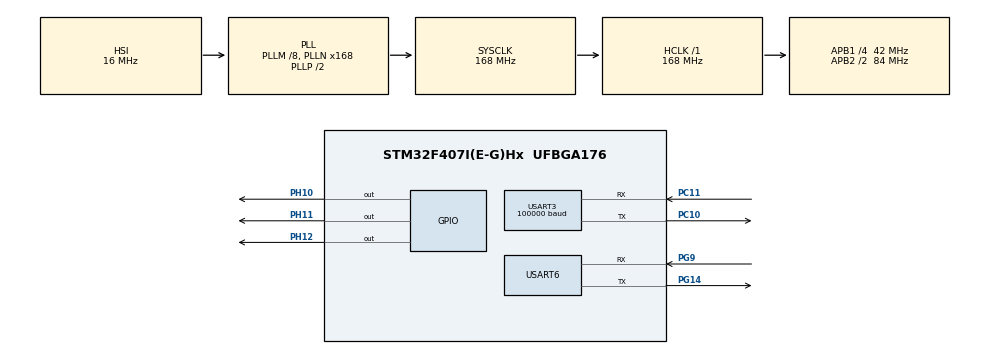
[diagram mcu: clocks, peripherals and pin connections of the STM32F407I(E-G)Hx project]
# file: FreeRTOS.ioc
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Dma.Request0=USART3_RX
Dma.USART3_RX.0.Direction=DMA_PERIPH_TO_MEMORY
Dma.USART3_RX.0.FIFOMode=DMA_FIFOMODE_DISABLE
Dma.USART3_RX.0.Instance=DMA1_Stream1
Dma.USART3_RX.0.MemDataAlignment=DMA_MDATAALIGN_BYTE
Dma.USART3_RX.0.MemInc=DMA_MINC_ENABLE
Dma.USART3_RX.0.Mode=DMA_CIRCULAR
Dma.USART3_RX.0.PeriphDataAlignment=DMA_PDATAALIGN_BYTE
Dma.USART3_RX.0.PeriphInc=DMA_PINC_DISABLE
Dma.USART3_RX.0.Priority=DMA_PRIORITY_VERY_HIGH
FREERTOS.Queues01=RCqueue,16,uint16_t,0,Dynamic,NULL,NULL
FREERTOS.Tasks01=LED_G,-2,256,LED_GTask,As weak,NULL,Dynamic,NULL,NULL;LED_R,-2,128,LED_RTask,As weak,NULL,Dynamic,NULL,NULL;UsartTask,0,128,usart_Task,Default,NULL,Dynamic,NULL,NULL
Mcu.Family=STM32F4
Mcu.Name=STM32F407I(E-G)Hx
Mcu.Package=UFBGA176
NVIC.DMA1_Stream1_IRQn=true\:5\:0\:false\:false\:true\:true\:false\:true\:true
NVIC.PriorityGroup=NVIC_PRIORITYGROUP_4
NVIC.TIM8_BRK_TIM12_IRQn=true\:15\:0\:false\:false\:true\:false\:false\:true\:true
NVIC.TimeBase=TIM8_BRK_TIM12_IRQn
NVIC.TimeBaseIP=TIM12
NVIC.USART3_IRQn=true\:5\:0\:false\:false\:true\:true\:true\:true\:true
NVIC.USART6_IRQn=true\:5\:0\:false\:false\:true\:true\:true\:true\:true
PA13.Mode=Serial_Wire
PA13.Signal=SYS_JTMS-SWDIO
PA14.Mode=Serial_Wire
PA14.Signal=SYS_JTCK-SWCLK
PC10.Mode=Asynchronous
PC10.Signal=USART3_TX
PC11.Mode=Asynchronous
PC11.Signal=USART3_RX
PG14.Mode=Asynchronous
PG14.Signal=USART6_TX
PG9.Mode=Asynchronous
PG9.Signal=USART6_RX
PH0-OSC_IN.Mode=HSE-External-Oscillator
PH0-OSC_IN.Signal=RCC_OSC_IN
PH1-OSC_OUT.Mode=HSE-External-Oscillator
PH1-OSC_OUT.Signal=RCC_OSC_OUT
PH10.PinState=GPIO_PIN_SET
PH10.Signal=GPIO_Output
PH11.GPIO_PuPd=GPIO_NOPULL
PH11.PinState=GPIO_PIN_RESET
PH11.Signal=GPIO_Output
PH12.GPIO_PuPd=GPIO_NOPULL
PH12.Signal=GPIO_Output
ProjectManager.HeapSize=0x200
ProjectManager.StackSize=0x400
ProjectManager.TargetToolchain=MDK-ARM V5.32
RCC.48MHZClocksFreq_Value=84000000
RCC.AHBFreq_Value=168000000
RCC.APB1CLKDivider=RCC_HCLK_DIV4
RCC.APB1Freq_Value=42000000
RCC.APB1TimFreq_Value=84000000
RCC.APB2CLKDivider=RCC_HCLK_DIV2
RCC.APB2Freq_Value=84000000
RCC.APB2TimFreq_Value=168000000
RCC.CortexFreq_Value=168000000
RCC.HCLKFreq_Value=168000000
RCC.HSE_VALUE=12000000
RCC.HSI_VALUE=16000000
RCC.LSE_VALUE=32768
RCC.PLLM=8
RCC.PLLN=168
RCC.SYSCLKFreq_VALUE=168000000
RCC.SYSCLKSource=RCC_SYSCLKSOURCE_PLLCLK
RCC.VCOOutputFreq_Value=336000000
USART3.BaudRate=100000
USART3.Parity=PARITY_EVEN
USART3.VirtualMode=VM_ASYNC
USART3.WordLength=WORDLENGTH_9B
USART6.VirtualMode=VM_ASYNC
VP_FREERTOS_VS_CMSIS_V1.Mode=CMSIS_V1
VP_SYS_VS_tim12.Mode=TIM12
board=custom

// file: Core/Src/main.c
/* USER CODE BEGIN Header */
/**
  ******************************************************************************
  * @file           : main.c
  * @brief          : Main program body
  ******************************************************************************
  * @attention
  *
  * Copyright (c) 2025 STMicroelectronics.
  * All rights reserved.
  *
  * This software is licensed under terms that can be found in the LICENSE file
  * in the root directory of this software component.
  * If no LICENSE file comes with this software, it is provided AS-IS.
  *
  ******************************************************************************
  */
/* USER CODE END Header */
#include "main.h"
#include "cmsis_os.h"
#include "dma.h"
#include "usart.h"
#include "gpio.h"

/* USER CODE BEGIN Includes */
#include "Usart1.h"
#include "Remote_Control.h"
/* USER CODE END Includes */

/* USER CODE BEGIN PV */
uint8_t sbus_buf[18];//遥控器的数据是18字节的
/* USER CODE END PV */

void SystemClock_Config(void);
void MX_FREERTOS_Init(void);
/* USER CODE BEGIN PFP */
void HAL_UART_RxCpltcallback(UART_HandleTypeDef *UartHandle);
/* USER CODE END PFP */

int main(void)
{

  /* MCU Configuration--------------------------------------------------------*/

  /* Reset of all peripherals, Initializes the Flash interface and the Systick. */
  HAL_Init();

  /* Configure the system clock */
  SystemClock_Config();

  /* Initialize all configured peripherals */
  MX_GPIO_Init();
  MX_DMA_Init();
  MX_USART3_UART_Init();
  MX_USART6_UART_Init();
  /* USER CODE BEGIN 2 */
  HAL_UART_Receive_DMA(&huart3, sbus_buf, 18);
  /* USER CODE END 2 */

  /* Call init function for freertos objects (in cmsis_os2.c) */
  MX_FREERTOS_Init();

  /* Start scheduler */
  osKernelStart();

  /* We should never get here as control is now taken by the scheduler */

  /* Infinite loop */
  while (1)
  {

  }
}

void SystemClock_Config(void)
{
  RCC_OscInitTypeDef RCC_OscInitStruct = {0};
  RCC_ClkInitTypeDef RCC_ClkInitStruct = {0};

  /** Configure the main internal regulator output voltage
  */
  __HAL_RCC_PWR_CLK_ENABLE();
  __HAL_PWR_VOLTAGESCALING_CONFIG(PWR_REGULATOR_VOLTAGE_SCALE1);

  /** Initializes the RCC Oscillators according to the specified parameters
  * in the RCC_OscInitTypeDef structure.
  */
  RCC_OscInitStruct.OscillatorType = RCC_OSCILLATORTYPE_HSI;
  RCC_OscInitStruct.HSIState = RCC_HSI_ON;
  RCC_OscInitStruct.HSICalibrationValue = RCC_HSICALIBRATION_DEFAULT;
  RCC_OscInitStruct.PLL.PLLState = RCC_PLL_ON;
  RCC_OscInitStruct.PLL.PLLSource = RCC_PLLSOURCE_HSI;
  RCC_OscInitStruct.PLL.PLLM = 8;
  RCC_OscInitStruct.PLL.PLLN = 168;
  RCC_OscInitStruct.PLL.PLLP = RCC_PLLP_DIV2;
  RCC_OscInitStruct.PLL.PLLQ = 4;
  if (HAL_RCC_OscConfig(&RCC_OscInitStruct) != HAL_OK)
  {
    Error_Handler();
  }

  /** Initializes the CPU, AHB and APB buses clocks
  */
  RCC_ClkInitStruct.ClockType = RCC_CLOCKTYPE_HCLK|RCC_CLOCKTYPE_SYSCLK
                              |RCC_CLOCKTYPE_PCLK1|RCC_CLOCKTYPE_PCLK2;
  RCC_ClkInitStruct.SYSCLKSource = RCC_SYSCLKSOURCE_PLLCLK;
  RCC_ClkInitStruct.AHBCLKDivider = RCC_SYSCLK_DIV1;
  RCC_ClkInitStruct.APB1CLKDivider = RCC_HCLK_DIV4;
  RCC_ClkInitStruct.APB2CLKDivider = RCC_HCLK_DIV2;

  if (HAL_RCC_ClockConfig(&RCC_ClkInitStruct, FLASH_LATENCY_5) != HAL_OK)
  {
    Error_Handler();
  }
}

void HAL_TIM_PeriodElapsedCallback(TIM_HandleTypeDef *htim)
{
  if (htim->Instance == TIM12)
  {
    HAL_IncTick();
  }
}

void Error_Handler(void)
{
  __disable_irq();
  while (1)
  {
  }
}

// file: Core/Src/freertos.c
/* USER CODE BEGIN Header */
/**
  ******************************************************************************
  * File Name          : freertos.c
  * Description        : Code for freertos applications
  ******************************************************************************
  * @attention
  *
  * Copyright (c) 2025 STMicroelectronics.
  * All rights reserved.
  *
  * This software is licensed under terms that can be found in the LICENSE file
  * in the root directory of this software component.
  * If no LICENSE file comes with this software, it is provided AS-IS.
  *
  ******************************************************************************
  */
/* USER CODE END Header */

#include "FreeRTOS.h"
#include "task.h"
#include "main.h"
#include "cmsis_os.h"

/* USER CODE BEGIN Includes */
#include "Usart1.h"
#include "usart.h"
/* USER CODE END Includes */

osThreadId LED_GHandle;
osThreadId LED_RHandle;
osThreadId UsartTaskHandle;
osMessageQId RCqueueHandle;

void LED_GTask(void const * argument);
void LED_RTask(void const * argument);
void usart_Task(void const * argument);

void MX_FREERTOS_Init(void); /* (MISRA C 2004 rule 8.1) */

/* GetIdleTaskMemory prototype (linked to static allocation support) */
void vApplicationGetIdleTaskMemory( StaticTask_t **ppxIdleTaskTCBBuffer, StackType_t **ppxIdleTaskStackBuffer, uint32_t *pulIdleTaskStackSize );

/* USER CODE BEGIN GET_IDLE_TASK_MEMORY */
static StaticTask_t xIdleTaskTCBBuffer;
static StackType_t xIdleStack[configMINIMAL_STACK_SIZE];

void vApplicationGetIdleTaskMemory( StaticTask_t **ppxIdleTaskTCBBuffer, StackType_t **ppxIdleTaskStackBuffer, uint32_t *pulIdleTaskStackSize )
{
  *ppxIdleTaskTCBBuffer = &xIdleTaskTCBBuffer;
  *ppxIdleTaskStackBuffer = &xIdleStack[0];
  *pulIdleTaskStackSize = configMINIMAL_STACK_SIZE;
  /* place for user code */
}
/* USER CODE END GET_IDLE_TASK_MEMORY */

void MX_FREERTOS_Init(void) {

  /* Create the queue(s) */
  /* definition and creation of RCqueue */
  osMessageQDef(RCqueue, 16, uint16_t);
  RCqueueHandle = osMessageCreate(osMessageQ(RCqueue), NULL);

  /* Create the thread(s) */
  /* definition and creation of LED_G */
  osThreadDef(LED_G, LED_GTask, osPriorityLow, 0, 256);
  LED_GHandle = osThreadCreate(osThread(LED_G), NULL);

  /* definition and creation of LED_R */
  osThreadDef(LED_R, LED_RTask, osPriorityLow, 0, 128);
  LED_RHandle = osThreadCreate(osThread(LED_R), NULL);

  /* definition and creation of UsartTask */
  osThreadDef(UsartTask, usart_Task, osPriorityNormal, 0, 128);
  UsartTaskHandle = osThreadCreate(osThread(UsartTask), NULL);

}

__weak void LED_GTask(void const * argument)
{
  for(;;)
  {
    osDelay(1);
  }
}

__weak void LED_RTask(void const * argument)
{
  for(;;)
  {
    osDelay(1);
  }
}

void usart_Task(void const * argument)
{
  /* USER CODE BEGIN usart_Task */
  /* Infinite loop */
  for(;;)
  {
		usart_Send();
		// FreeRTOS延时（使用时间转换宏）
		osDelay(500);
		//vTaskDelay(pdMS_TO_TICKS(1000));

  }
  /* USER CODE END usart_Task */
}
